# STM32F7x7 register map
File version: 1.4
CPU: CM7 r0p1, little endian, MPU, FPU, VTOR, 4 interrupt priority bits
Registers are 32-bit, read-write, reset 0x0 unless marked. A register's access mark holds for its fields unless they carry their own. Offsets are from the block's base; [hi:lo] are bit positions; {n}, {i} and the like mark numbered series.

## MDIOS — Management data input/output slave
Base 0x40017800
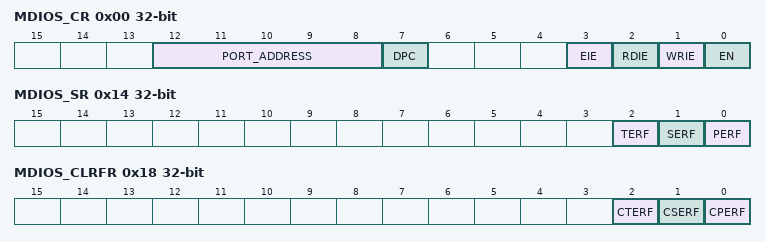
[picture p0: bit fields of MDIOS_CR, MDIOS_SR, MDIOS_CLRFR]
0x00 MDIOS_CR — MDIOS configuration register
  [12:8] PORT_ADDRESS — Slaves's address
  [7] DPC — Disable Preamble Check
  [3] EIE — Error interrupt enable
  [2] RDIE — Register Read Interrupt Enable
  [1] WRIE — Register write interrupt enable
  [0] EN — Peripheral enable
0x04 MDIOS_WRFR ro — MDIOS write flag register
  [31:0] WRF — Write flags for MDIO registers 0 to 31
0x08 MDIOS_CWRFR — MDIOS clear write flag register
  [31:0] CWRF — Clear the write flag
0x0C MDIOS_RDFR ro — MDIOS read flag register
  [31:0] RDF — Read flags for MDIO registers 0 to 31
0x10 MDIOS_CRDFR — MDIOS clear read flag register
  [31:0] CRDF — Clear the read flag
0x14 MDIOS_SR ro — MDIOS status register
  [2] TERF — Turnaround error flag
  [1] SERF — Start error flag
  [0] PERF — Preamble error flag
0x18 MDIOS_CLRFR — MDIOS clear flag register
  [2] CTERF — Clear the turnaround error flag
  [1] CSERF — Clear the start error flag
  [0] CPERF — Clear the preamble error flag
{0x1C+4i} MDIOS_DINR{i} ro (i=0..31) — MDIOS input data register {i}
  [15:0] DIN{i} — Input data received from MDIO Master during write frames
{0x9C+4i} MDIOS_DOUTR{i} (i=0..31) — MDIOS output data register {i}
  [15:0] DOUT{i} — Output data sent to MDIO Master during read frames

## JPEG — JPEG codec
Base 0x50051000
0x00 JPEG_CONFR0 wo — JPEG codec configuration register 0
  [0] START
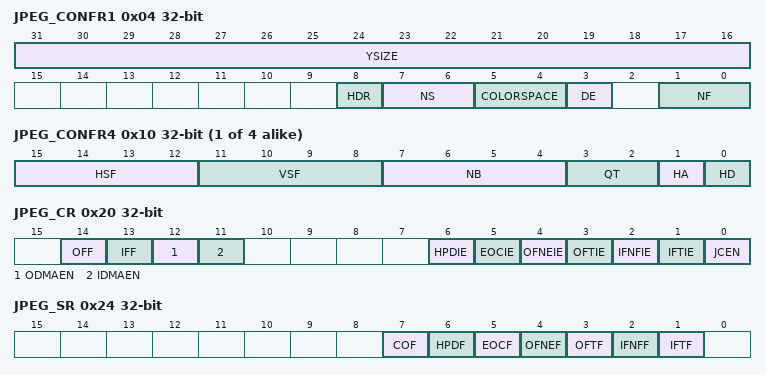
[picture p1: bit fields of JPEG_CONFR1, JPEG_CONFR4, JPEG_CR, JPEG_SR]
0x04 JPEG_CONFR1 — JPEG codec configuration register 1
  [31:16] YSIZE
  [8] HDR — Header Processing
  [7:6] NS — Number of components for Scan
  [5:4] COLORSPACE
  [3] DE — Decoding Enable
  [1:0] NF — Number of color components
0x08 JPEG_CONFR2 — JPEG codec configuration register 2
  [25:0] NMCU — Number of MCU
0x0C JPEG_CONFR3 — JPEG codec configuration register 3
  [31:16] XSIZE
{0x0+4i} JPEG_CONFR{i} (i=4..7) — JPEG codec configuration register {i}
  [15:12] HSF — Horizontal Sampling Factor
  [11:8] VSF — Vertical Sampling Factor
  [7:4] NB — Number of Block
  [3:2] QT — Quantization Table
  [1] HA — Huffman AC
  [0] HD — Huffman DC
0x20 JPEG_CR access per field — JPEG control register
  [14] OFF ro — Output FIFO Flush
  [13] IFF ro — Input FIFO Flush
  [12] ODMAEN rw — Output DMA Enable
  [11] IDMAEN rw — Input DMA Enable
  [6] HPDIE rw — Header Parsing Done Interrupt Enable
  [5] EOCIE rw — End of Conversion Interrupt Enable
  [4] OFNEIE rw — Output FIFO Not Empty Interrupt Enable
  [3] OFTIE rw — Output FIFO Threshold Interrupt Enable
  [2] IFNFIE rw — Input FIFO Not Full Interrupt Enable
  [1] IFTIE rw — Input FIFO Threshold Interrupt Enable
  [0] JCEN rw — JPEG Core Enable
0x24 JPEG_SR ro — JPEG status register
  [7] COF — Codec Operation Flag
  [6] HPDF — Header Parsing Done Flag
  [5] EOCF — End of Conversion Flag
  [4] OFNEF — Output FIFO Not Empty Flag
  [3] OFTF — Output FIFO Threshold Flag
  [2] IFNFF — Input FIFO Not Full Flag
  [1] IFTF — Input FIFO Threshold Flag
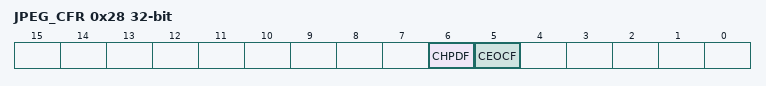
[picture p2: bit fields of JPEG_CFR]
0x28 JPEG_CFR wo — JPEG clear flag register
  [6] CHPDF — Clear Header Parsing Done Flag
  [5] CEOCF — Clear End of Conversion Flag
0x2C JPEG_DIR wo — JPEG data input register
  [31:0] DATAIN — Data Input FIFO
0x30 JPEG_DOR ro — JPEG data output register
  [31:0] DATAOUT — Data Output FIFO

## Ethernet_MMC — Ethernet: MAC management counters
Base 0x40028100
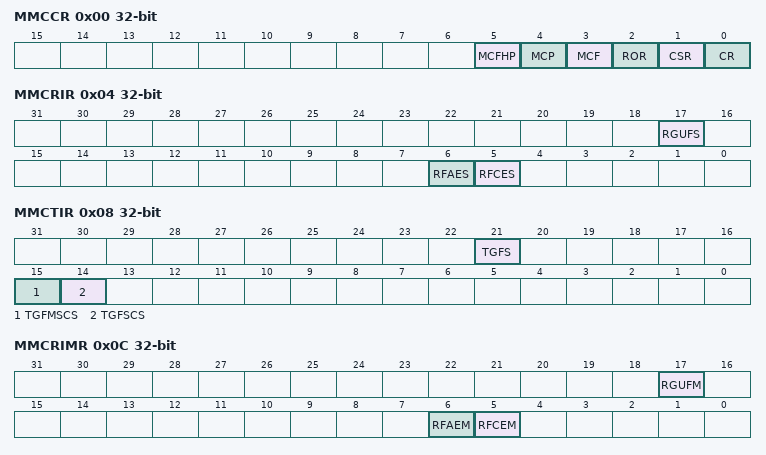
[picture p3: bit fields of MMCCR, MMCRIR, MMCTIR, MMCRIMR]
0x00 MMCCR — Ethernet MMC control register
  [5] MCFHP, [4] MCP, [3] MCF, [2] ROR, [1] CSR, [0] CR
0x04 MMCRIR — Ethernet MMC receive interrupt register
  [17] RGUFS, [6] RFAES, [5] RFCES
0x08 MMCTIR ro — Ethernet MMC transmit interrupt register
  [21] TGFS, [15] TGFMSCS, [14] TGFSCS
0x0C MMCRIMR — Ethernet MMC receive interrupt mask register
  [17] RGUFM, [6] RFAEM, [5] RFCEM
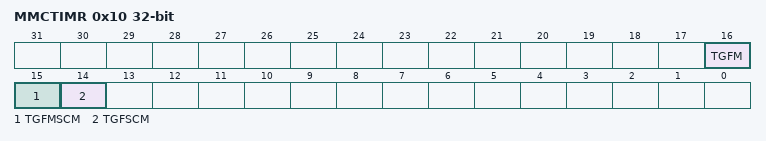
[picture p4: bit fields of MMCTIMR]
0x10 MMCTIMR — Ethernet MMC transmit interrupt mask register
  [16] TGFM, [15] TGFMSCM, [14] TGFSCM
0x4C MMCTGFSCCR ro — Ethernet MMC transmitted good frames after a single collision counter
  [31:0] TGFSCC
0x50 MMCTGFMSCCR ro — Ethernet MMC transmitted good frames after more than a single collision
  [31:0] TGFMSCC
0x68 MMCTGFCR ro — Ethernet MMC transmitted good frames counter register
  [31:0] TGFC — HTL
0x94 MMCRFCECR ro — Ethernet MMC received frames with CRC error counter register
  [31:0] RFCFC
0x98 MMCRFAECR ro — Ethernet MMC received frames with alignment error counter register
  [31:0] RFAEC
0xC4 MMCRGUFCR ro — MMC received good unicast frames counter register
  [31:0] RGUFC

## Ethernet_PTP — Ethernet: Precision time protocol
Base 0x40028700
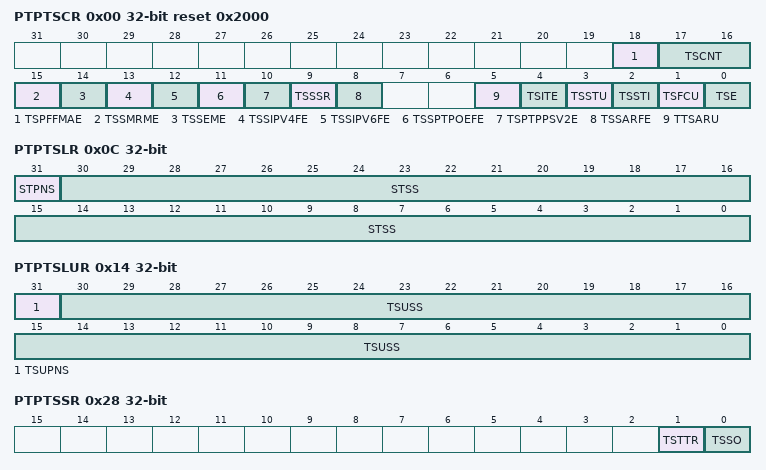
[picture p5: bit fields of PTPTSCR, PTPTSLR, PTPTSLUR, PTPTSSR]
0x00 PTPTSCR reset 0x2000 — Ethernet PTP time stamp control register
  [18] TSPFFMAE, [17:16] TSCNT, [15] TSSMRME, [14] TSSEME, [13] TSSIPV4FE, [12] TSSIPV6FE, [11] TSSPTPOEFE, [10] TSPTPPSV2E, [9] TSSSR, [8] TSSARFE, [5] TTSARU, [4] TSITE, [3] TSSTU, [2] TSSTI, [1] TSFCU, [0] TSE
0x04 PTPSSIR — Ethernet PTP subsecond increment register
  [7:0] STSSI
0x08 PTPTSHR ro — Ethernet PTP time stamp high register
  [31:0] STS
0x0C PTPTSLR ro — Ethernet PTP time stamp low register
  [31] STPNS, [30:0] STSS
0x10 PTPTSHUR — Ethernet PTP time stamp high update register
  [31:0] TSUS
0x14 PTPTSLUR — Ethernet PTP time stamp low update register
  [31] TSUPNS, [30:0] TSUSS
0x18 PTPTSAR — Ethernet PTP time stamp addend register
  [31:0] TSA
0x1C PTPTTHR — Ethernet PTP target time high register
  [31:0] TTSH — 0
0x20 PTPTTLR — Ethernet PTP target time low register
  [31:0] TTSL
0x28 PTPTSSR ro — Ethernet PTP time stamp status register
  [1] TSTTR, [0] TSSO
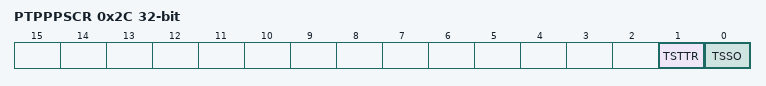
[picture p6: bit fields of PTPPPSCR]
0x2C PTPPPSCR ro — Ethernet PTP PPS control register
  [1] TSTTR, [0] TSSO

## Ethernet_DMA — Ethernet: DMA controller operation
Base 0x40029000
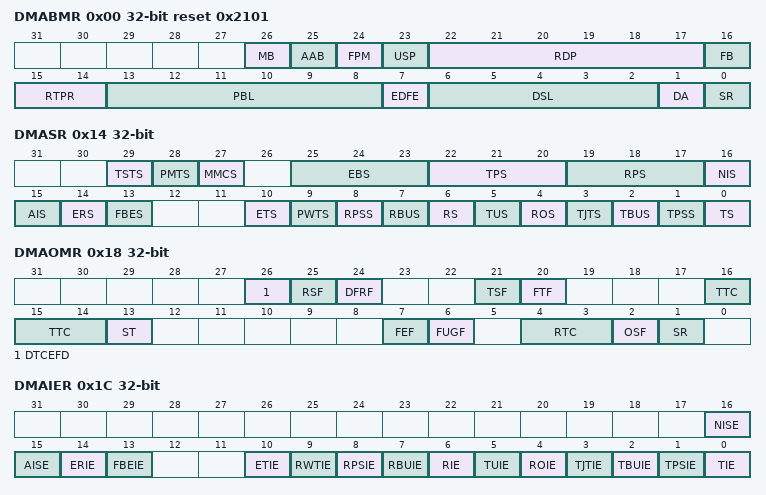
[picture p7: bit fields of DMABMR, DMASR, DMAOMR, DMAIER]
0x00 DMABMR reset 0x2101 — Ethernet DMA bus mode register
  [26] MB, [25] AAB, [24] FPM, [23] USP, [22:17] RDP, [16] FB, [15:14] RTPR, [13:8] PBL, [7] EDFE, [6:2] DSL, [1] DA, [0] SR
0x04 DMATPDR — Ethernet DMA transmit poll demand register
  [31:0] TPD
0x08 DMARPDR — EHERNET DMA receive poll demand register
  [31:0] RPD
0x0C DMARDLAR — Ethernet DMA receive descriptor list address register
  [31:0] SRL
0x10 DMATDLAR — Ethernet DMA transmit descriptor list address register
  [31:0] STL
0x14 DMASR access per field — Ethernet DMA status register
  [29] TSTS ro, [28] PMTS ro, [27] MMCS ro, [25:23] EBS ro, [22:20] TPS ro, [19:17] RPS ro, [16] NIS rw, [15] AIS rw, [14] ERS rw, [13] FBES rw, [10] ETS rw, [9] PWTS rw, [8] RPSS rw, [7] RBUS rw, [6] RS rw, [5] TUS rw, [4] ROS rw, [3] TJTS rw, [2] TBUS rw, [1] TPSS rw, [0] TS rw
0x18 DMAOMR — Ethernet DMA operation mode register
  [26] DTCEFD, [25] RSF, [24] DFRF, [21] TSF, [20] FTF, [16:14] TTC, [13] ST, [7] FEF, [6] FUGF, [4:3] RTC, [2] OSF, [1] SR
0x1C DMAIER — Ethernet DMA interrupt enable register
  [16] NISE, [15] AISE, [14] ERIE, [13] FBEIE, [10] ETIE, [9] RWTIE, [8] RPSIE, [7] RBUIE, [6] RIE, [5] TUIE, [4] ROIE, [3] TJTIE, [2] TBUIE, [1] TPSIE, [0] TIE
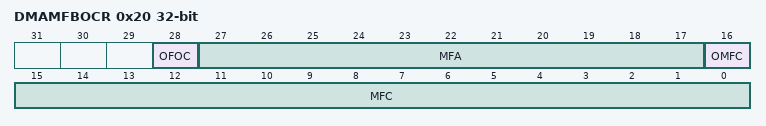
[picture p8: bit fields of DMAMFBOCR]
0x20 DMAMFBOCR — Ethernet DMA missed frame and buffer overflow counter register
  [28] OFOC, [27:17] MFA, [16] OMFC, [15:0] MFC
0x24 DMARSWTR — Ethernet DMA receive status watchdog timer register
  [7:0] RSWTC
0x48 DMACHTDR ro — Ethernet DMA current host transmit descriptor register
  [31:0] HTDAP
0x4C DMACHRDR ro — Ethernet DMA current host receive descriptor register
  [31:0] HRDAP
0x50 DMACHTBAR ro — Ethernet DMA current host transmit buffer address register
  [31:0] HTBAP
0x54 DMACHRBAR ro — Ethernet DMA current host receive buffer address register
  [31:0] HRBAP

## OTG_FS_PWRCLK — USB on the go full speed
Base 0x50000E00
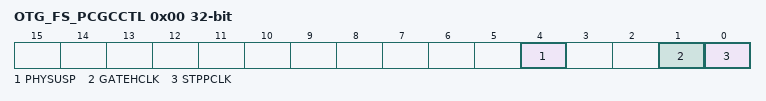
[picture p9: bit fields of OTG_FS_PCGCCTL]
0x00 OTG_FS_PCGCCTL — OTG_FS power and clock gating control register (OTG_FS_PCGCCTL)
  [4] PHYSUSP — PHY Suspended
  [1] GATEHCLK
  [0] STPPCLK — Stop PHY clock

## OTG_HS_PWRCLK — USB on the go high speed
Base 0x40040E00
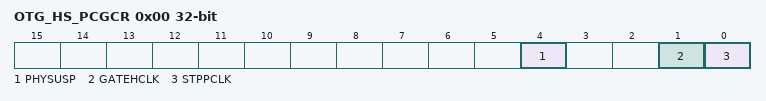
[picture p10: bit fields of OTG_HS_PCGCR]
0x00 OTG_HS_PCGCR — Power and clock gating control register
  [4] PHYSUSP — PHY suspended
  [1] GATEHCLK
  [0] STPPCLK — Stop PHY clock
